# bao1x_peri register map
Vendor: baochip
Registers are 32-bit, read-write, reset 0x0 unless marked. A register's access mark holds for its fields unless they carry their own. Offsets are from the block's base; [hi:lo] are bit positions; {n}, {i} and the like mark numbered series; <NAME> marks a mode.

## AES
Base 0x4002D000
0x00 SFR_CRFUNC — See `aes.sv#L140 <https://github.com/baochip/baochip-1x/blob/main/rtl/modules/cr ypto_top/rtl/aes.sv#L140>`__ (line numbers are approximate)
  [7:0] sfr_crfunc — sfr_crfunc read/write control register
0x04 SFR_AR — See `aes.sv#L141 <https://github.com/baochip/baochip-1x/blob/main/rtl/modules/cr ypto_top/rtl/aes.sv#L141>`__ (line numbers are approximate)
  [31:0] sfr_ar — sfr_ar performs action on write of value: 0x5a
0x08 SFR_SRMFSM — See `aes.sv#L142 <https://github.com/baochip/baochip-1x/blob/main/rtl/modules/cr ypto_top/rtl/aes.sv#L142>`__ (line numbers are approximate)
  [7:0] sfr_srmfsm — sfr_srmfsm read only status register
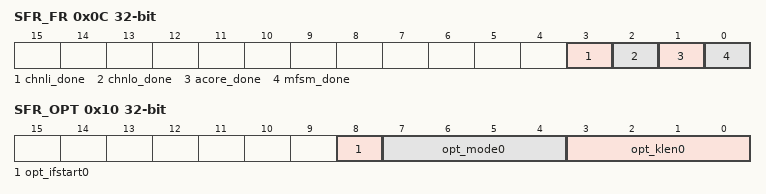
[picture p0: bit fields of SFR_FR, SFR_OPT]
0x0C SFR_FR — See `aes.sv#L143 <https://github.com/baochip/baochip-1x/blob/main/rtl/modules/cr ypto_top/rtl/aes.sv#L143>`__ (line numbers are approximate)
  [3] chnli_done — chnli_done flag register. `1` means event happened, write back `1` in respective bit position to clear the flag
  [2] chnlo_done — chnlo_done flag register. `1` means event happened, write back `1` in respective bit position to clear the flag
  [1] acore_done — acore_done flag register. `1` means event happened, write back `1` in respective bit position to clear the flag
  [0] mfsm_done — mfsm_done flag register. `1` means event happened, write back `1` in respective bit position to clear the flag
0x10 SFR_OPT — See `aes.sv#L145 <https://github.com/baochip/baochip-1x/blob/main/rtl/modules/cr ypto_top/rtl/aes.sv#L145>`__ (line numbers are approximate)
  [8] opt_ifstart0 — opt_ifstart0 read/write control register
  [7:4] opt_mode0 — opt_mode0 read/write control register
  [3:0] opt_klen0 — opt_klen0 read/write control register
0x14 SFR_OPT1 — See `aes.sv#L146 <https://github.com/baochip/baochip-1x/blob/main/rtl/modules/cr ypto_top/rtl/aes.sv#L146>`__ (line numbers are approximate)
  [15:0] sfr_opt1 — sfr_opt1 read/write control register
0x18 SFR_OPTLTX — See `aes.sv#L147 <https://github.com/baochip/baochip-1x/blob/main/rtl/modules/cr ypto_top/rtl/aes.sv#L147>`__ (line numbers are approximate)
  [5:0] sfr_optltx — sfr_optltx read/write control register
0x20 SFR_MASKSEED — See `aes.sv#L150 <https://github.com/baochip/baochip-1x/blob/main/rtl/modules/cr ypto_top/rtl/aes.sv#L150>`__ (line numbers are approximate)
  [31:0] sfr_maskseed — sfr_maskseed read/write control register
0x24 SFR_MASKSEEDAR — See `aes.sv#L151 <https://github.com/baochip/baochip-1x/blob/main/rtl/modules/cr ypto_top/rtl/aes.sv#L151>`__ (line numbers are approximate)
  [31:0] sfr_maskseedar — sfr_maskseedar performs action on write of value: 0x5a
0x30 SFR_SEGPTR_PTRID_IV — See `aes.sv#L153 <https://github.com/baochip/baochip-1x/blob/main/rtl/modules/cr ypto_top/rtl/aes.sv#L153>`__ (line numbers are approximate)
  [11:0] PTRID_IV — cr_segptrstart read/write control register
0x34 SFR_SEGPTR_PTRID_AKEY — See `aes.sv#L153 <https://github.com/baochip/baochip-1x/blob/main/rtl/modules/cr ypto_top/rtl/aes.sv#L153>`__ (line numbers are approximate)
  [11:0] PTRID_AKEY — cr_segptrstart read/write control register
0x38 SFR_SEGPTR_PTRID_AIB — See `aes.sv#L153 <https://github.com/baochip/baochip-1x/blob/main/rtl/modules/cr ypto_top/rtl/aes.sv#L153>`__ (line numbers are approximate)
  [11:0] PTRID_AIB — cr_segptrstart read/write control register
0x3C SFR_SEGPTR_PTRID_AOB — See `aes.sv#L153 <https://github.com/baochip/baochip-1x/blob/main/rtl/modules/cr ypto_top/rtl/aes.sv#L153>`__ (line numbers are approximate)
  [11:0] PTRID_AOB — cr_segptrstart read/write control register

## TRNG
Base 0x4002E000
0x00 SFR_CRSRC — See `trng.sv#L105 <https://github.com/baochip/baochip-1x/blob/main/rtl/modules/c rypto_top/rtl/trng.sv#L105>`__ (line numbers are approximate)
  [12:0] sfr_crsrc — sfr_crsrc read/write control register
0x04 SFR_CRANA — See `trng.sv#L106 <https://github.com/baochip/baochip-1x/blob/main/rtl/modules/c rypto_top/rtl/trng.sv#L106>`__ (line numbers are approximate)
  [15:0] sfr_crana — sfr_crana read/write control register
0x08 SFR_PP — See `trng.sv#L107 <https://github.com/baochip/baochip-1x/blob/main/rtl/modules/c rypto_top/rtl/trng.sv#L107>`__ (line numbers are approximate)
  [16:0] sfr_pp — sfr_pp read/write control register
0x0C SFR_OPT — See `trng.sv#L108 <https://github.com/baochip/baochip-1x/blob/main/rtl/modules/c rypto_top/rtl/trng.sv#L108>`__ (line numbers are approximate)
  [16:0] sfr_opt — sfr_opt read/write control register
0x10 SFR_SR — See `trng.sv#L114 <https://github.com/baochip/baochip-1x/blob/main/rtl/modules/c rypto_top/rtl/trng.sv#L114>`__ (line numbers are approximate)
  [31:0] sr_rng — sr_rng read only status register
0x14 SFR_AR_GEN — See `trng.sv#L112 <https://github.com/baochip/baochip-1x/blob/main/rtl/modules/c rypto_top/rtl/trng.sv#L112>`__ (line numbers are approximate)
  [31:0] sfr_ar_gen — sfr_ar_gen performs action on write of value: 0x55
0x18 SFR_FR — See `trng.sv#L115 <https://github.com/baochip/baochip-1x/blob/main/rtl/modules/c rypto_top/rtl/trng.sv#L115>`__ (line numbers are approximate)
  [2:0] sfr_fr — sfr_fr flag register. `1` means event happened, write back `1` in respective bit position to clear the flag
0x20 SFR_DRPSZ — See `trng.sv#L239 <https://github.com/baochip/baochip-1x/blob/main/rtl/modules/c rypto_top/rtl/trng.sv#L239>`__ (line numbers are approximate)
  [31:0] sfr_drpsz — sfr_drpsz read/write control register
0x24 SFR_DRGEN — See `trng.sv#L240 <https://github.com/baochip/baochip-1x/blob/main/rtl/modules/c rypto_top/rtl/trng.sv#L240>`__ (line numbers are approximate)
  [31:0] sfr_drgen — sfr_drgen read/write control register
0x28 SFR_DRRESEED — See `trng.sv#L241 <https://github.com/baochip/baochip-1x/blob/main/rtl/modules/c rypto_top/rtl/trng.sv#L241>`__ (line numbers are approximate)
  [31:0] sfr_drreseed — sfr_drreseed read/write control register
0x30 SFR_BUF — See `trng.sv#L242 <https://github.com/baochip/baochip-1x/blob/main/rtl/modules/c rypto_top/rtl/trng.sv#L242>`__ (line numbers are approximate)
  [31:0] sfr_buf — sfr_buf read only status register
{0x40+4i} SFR_CHAIN_RNGCHAINEN{i} (i=0..3) — See `trng.sv#L117 <https://github.com/baochip/baochip-1x/blob/main/rtl/modules/c rypto_top/rtl/trng.sv#L117>`__ (line numbers are approximate)
  [31:0] rngchainen{i} — rngchainen read/write control register
